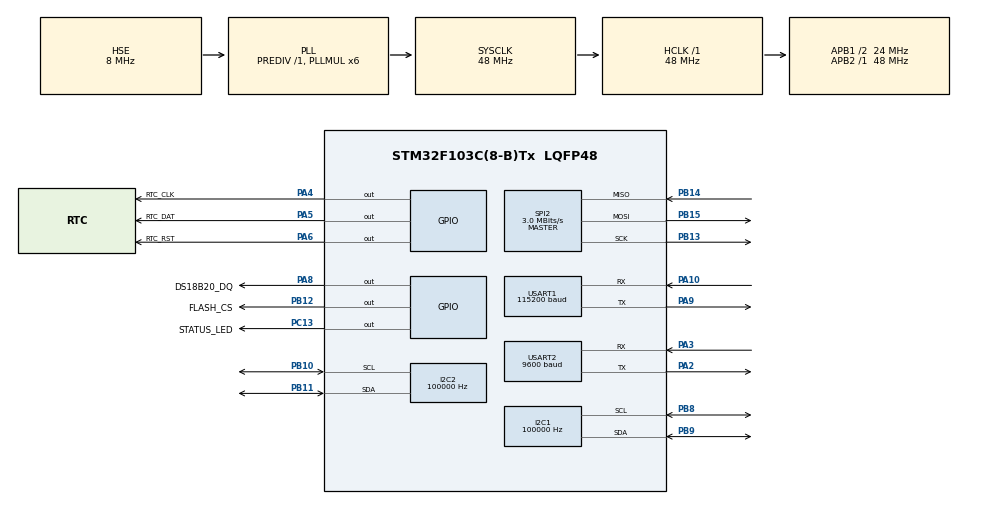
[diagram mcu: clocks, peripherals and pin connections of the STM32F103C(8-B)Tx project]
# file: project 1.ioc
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I2C1.ClockSpeed=100000
I2C2.ClockSpeed=100000
Mcu.Family=STM32F1
Mcu.Name=STM32F103C(8-B)Tx
Mcu.Package=LQFP48
NVIC.PriorityGroup=NVIC_PRIORITYGROUP_4
NVIC.USART1_IRQn=true\:0\:0\:false\:false\:true\:true\:true\:true
NVIC.USART2_IRQn=true\:1\:0\:false\:false\:true\:true\:true\:true
PA10.Mode=Asynchronous
PA10.Signal=USART1_RX
PA2.Mode=Asynchronous
PA2.Signal=USART2_TX
PA3.Mode=Asynchronous
PA3.Signal=USART2_RX
PA4.GPIO_Label=RTC_CLK
PA4.GPIO_Speed=GPIO_SPEED_FREQ_LOW
PA4.PinState=GPIO_PIN_RESET
PA4.Signal=GPIO_Output
PA5.GPIO_Label=RTC_DAT
PA5.GPIO_Speed=GPIO_SPEED_FREQ_LOW
PA5.PinState=GPIO_PIN_RESET
PA5.Signal=GPIO_Output
PA6.GPIO_Label=RTC_RST
PA6.GPIO_Speed=GPIO_SPEED_FREQ_LOW
PA6.PinState=GPIO_PIN_RESET
PA6.Signal=GPIO_Output
PA13.Mode=Serial_Wire
PA13.Signal=SYS_JTMS-SWDIO
PA14.Mode=Serial_Wire
PA14.Signal=SYS_JTCK-SWCLK
PA8.GPIO_Label=DS18B20_DQ
PA8.GPIO_ModeDefaultOutputPP=GPIO_MODE_OUTPUT_OD
PA8.GPIO_PuPd=GPIO_NOPULL
PA8.GPIO_Speed=GPIO_SPEED_FREQ_HIGH
PA8.PinState=GPIO_PIN_SET
PA8.Signal=GPIO_Output
PA9.Mode=Asynchronous
PA9.Signal=USART1_TX
PB13.Mode=Full_Duplex_Master
PB13.Signal=SPI2_SCK
PB14.Mode=Full_Duplex_Master
PB14.Signal=SPI2_MISO
PB15.Mode=Full_Duplex_Master
PB15.Signal=SPI2_MOSI
PB10.Mode=I2C
PB10.Signal=I2C2_SCL
PB11.Mode=I2C
PB11.Signal=I2C2_SDA
PB12.GPIO_Label=FLASH_CS
PB12.GPIO_Speed=GPIO_SPEED_FREQ_HIGH
PB12.PinState=GPIO_PIN_SET
PB12.Signal=GPIO_Output
PB8.Mode=I2C
PB8.Signal=I2C1_SCL
PB9.Mode=I2C
PB9.Signal=I2C1_SDA
PC13-TAMPER-RTC.GPIO_Label=STATUS_LED
PC13-TAMPER-RTC.PinState=GPIO_PIN_SET
PC13-TAMPER-RTC.Signal=GPIO_Output
PD0-OSC_IN.Mode=HSE-External-Oscillator
PD0-OSC_IN.Signal=RCC_OSC_IN
PD1-OSC_OUT.Mode=HSE-External-Oscillator
PD1-OSC_OUT.Signal=RCC_OSC_OUT
ProjectManager.HeapSize=0x200
ProjectManager.StackSize=0x400
ProjectManager.TargetToolchain=STM32CubeIDE
RCC.AHBFreq_Value=48000000
RCC.APB1CLKDivider=RCC_HCLK_DIV2
RCC.APB1Freq_Value=24000000
RCC.APB1TimFreq_Value=48000000
RCC.APB2Freq_Value=48000000
RCC.APB2TimFreq_Value=48000000
RCC.HCLKFreq_Value=48000000
RCC.PLLMUL=RCC_PLL_MUL6
RCC.PLLSourceVirtual=RCC_PLLSOURCE_HSE
RCC.SYSCLKFreq_VALUE=48000000
RCC.SYSCLKSource=RCC_SYSCLKSOURCE_PLLCLK
RCC.USBFreq_Value=48000000
SPI2.BaudRatePrescaler=SPI_BAUDRATEPRESCALER_8
SPI2.CalculateBaudRate=3.0 MBits/s
SPI2.Direction=SPI_DIRECTION_2LINES
SPI2.Mode=SPI_MODE_MASTER
SPI2.VirtualType=VM_MASTER
USART1.BaudRate=115200
USART1.VirtualMode=VM_ASYNC
USART2.BaudRate=9600
USART2.VirtualMode=VM_ASYNC
board=custom

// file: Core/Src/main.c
/* USER CODE BEGIN Header */
/**
  ******************************************************************************
  * @file           : main.c
  * @brief          : Main program body
  ******************************************************************************
  */
/* USER CODE END Header */
#include "main.h"

/* USER CODE BEGIN Includes */
#include "app.h"
/* USER CODE END Includes */

I2C_HandleTypeDef hi2c1;
I2C_HandleTypeDef hi2c2;

SPI_HandleTypeDef hspi2;

UART_HandleTypeDef huart1;
UART_HandleTypeDef huart2;

void SystemClock_Config(void);
static void MX_GPIO_Init(void);
static void MX_USART1_UART_Init(void);
static void MX_USART2_UART_Init(void);
static void MX_SPI2_Init(void);
static void MX_I2C1_Init(void);
static void MX_I2C2_Init(void);

int main(void)
{

  /* MCU Configuration--------------------------------------------------------*/

  /* Reset of all peripherals, Initializes the Flash interface and the Systick. */
  HAL_Init();

  /* Configure the system clock */
  SystemClock_Config();

  /* Initialize all configured peripherals */
  MX_GPIO_Init();
  MX_USART1_UART_Init();
  MX_USART2_UART_Init();
  MX_SPI2_Init();
  MX_I2C1_Init();
  MX_I2C2_Init();
  /* USER CODE BEGIN 2 */
  App_Init(&huart1, &huart2, &hi2c1, &hi2c2, &hspi2);
  /* USER CODE END 2 */

  /* Infinite loop */
  while (1)
  {

    /* USER CODE BEGIN 3 */
    App_Process();
    HAL_Delay(1U);
  }
  /* USER CODE END 3 */
}

void SystemClock_Config(void)
{
  RCC_OscInitTypeDef RCC_OscInitStruct = {0};
  RCC_ClkInitTypeDef RCC_ClkInitStruct = {0};

  /** Initializes the RCC Oscillators according to the specified parameters
  * in the RCC_OscInitTypeDef structure.
  */
  RCC_OscInitStruct.OscillatorType = RCC_OSCILLATORTYPE_HSE;
  RCC_OscInitStruct.HSEState = RCC_HSE_ON;
  RCC_OscInitStruct.HSEPredivValue = RCC_HSE_PREDIV_DIV1;
  RCC_OscInitStruct.HSIState = RCC_HSI_ON;
  RCC_OscInitStruct.PLL.PLLState = RCC_PLL_ON;
  RCC_OscInitStruct.PLL.PLLSource = RCC_PLLSOURCE_HSE;
  RCC_OscInitStruct.PLL.PLLMUL = RCC_PLL_MUL6;
  if (HAL_RCC_OscConfig(&RCC_OscInitStruct) != HAL_OK)
  {
    Error_Handler();
  }

  /** Initializes the CPU, AHB and APB buses clocks
  */
  RCC_ClkInitStruct.ClockType = RCC_CLOCKTYPE_HCLK|RCC_CLOCKTYPE_SYSCLK
                              |RCC_CLOCKTYPE_PCLK1|RCC_CLOCKTYPE_PCLK2;
  RCC_ClkInitStruct.SYSCLKSource = RCC_SYSCLKSOURCE_PLLCLK;
  RCC_ClkInitStruct.AHBCLKDivider = RCC_SYSCLK_DIV1;
  RCC_ClkInitStruct.APB1CLKDivider = RCC_HCLK_DIV2;
  RCC_ClkInitStruct.APB2CLKDivider = RCC_HCLK_DIV1;

  if (HAL_RCC_ClockConfig(&RCC_ClkInitStruct, FLASH_LATENCY_1) != HAL_OK)
  {
    Error_Handler();
  }
}

static void MX_I2C1_Init(void)
{

  hi2c1.Instance = I2C1;
  hi2c1.Init.ClockSpeed = 100000;
  hi2c1.Init.DutyCycle = I2C_DUTYCYCLE_2;
  hi2c1.Init.OwnAddress1 = 0;
  hi2c1.Init.AddressingMode = I2C_ADDRESSINGMODE_7BIT;
  hi2c1.Init.DualAddressMode = I2C_DUALADDRESS_DISABLE;
  hi2c1.Init.OwnAddress2 = 0;
  hi2c1.Init.GeneralCallMode = I2C_GENERALCALL_DISABLE;
  hi2c1.Init.NoStretchMode = I2C_NOSTRETCH_DISABLE;
  if (HAL_I2C_Init(&hi2c1) != HAL_OK)
  {
    Error_Handler();
  }

}

static void MX_I2C2_Init(void)
{

  hi2c2.Instance = I2C2;
  hi2c2.Init.ClockSpeed = 100000;
  hi2c2.Init.DutyCycle = I2C_DUTYCYCLE_2;
  hi2c2.Init.OwnAddress1 = 0;
  hi2c2.Init.AddressingMode = I2C_ADDRESSINGMODE_7BIT;
  hi2c2.Init.DualAddressMode = I2C_DUALADDRESS_DISABLE;
  hi2c2.Init.OwnAddress2 = 0;
  hi2c2.Init.GeneralCallMode = I2C_GENERALCALL_DISABLE;
  hi2c2.Init.NoStretchMode = I2C_NOSTRETCH_DISABLE;
  if (HAL_I2C_Init(&hi2c2) != HAL_OK)
  {
    Error_Handler();
  }

}

static void MX_SPI2_Init(void)
{

  /* SPI2 parameter configuration*/
  hspi2.Instance = SPI2;
  hspi2.Init.Mode = SPI_MODE_MASTER;
  hspi2.Init.Direction = SPI_DIRECTION_2LINES;
  hspi2.Init.DataSize = SPI_DATASIZE_8BIT;
  hspi2.Init.CLKPolarity = SPI_POLARITY_LOW;
  hspi2.Init.CLKPhase = SPI_PHASE_1EDGE;
  hspi2.Init.NSS = SPI_NSS_SOFT;
  hspi2.Init.BaudRatePrescaler = SPI_BAUDRATEPRESCALER_8;
  hspi2.Init.FirstBit = SPI_FIRSTBIT_MSB;
  hspi2.Init.TIMode = SPI_TIMODE_DISABLE;
  hspi2.Init.CRCCalculation = SPI_CRCCALCULATION_DISABLE;
  hspi2.Init.CRCPolynomial = 10;
  if (HAL_SPI_Init(&hspi2) != HAL_OK)
  {
    Error_Handler();
  }

}

static void MX_USART1_UART_Init(void)
{

  huart1.Instance = USART1;
  huart1.Init.BaudRate = 115200;
  huart1.Init.WordLength = UART_WORDLENGTH_8B;
  huart1.Init.StopBits = UART_STOPBITS_1;
  huart1.Init.Parity = UART_PARITY_NONE;
  huart1.Init.Mode = UART_MODE_TX_RX;
  huart1.Init.HwFlowCtl = UART_HWCONTROL_NONE;
  huart1.Init.OverSampling = UART_OVERSAMPLING_16;
  if (HAL_UART_Init(&huart1) != HAL_OK)
  {
    Error_Handler();
  }

}

static void MX_USART2_UART_Init(void)
{

  huart2.Instance = USART2;
  huart2.Init.BaudRate = 9600;
  huart2.Init.WordLength = UART_WORDLENGTH_8B;
  huart2.Init.StopBits = UART_STOPBITS_1;
  huart2.Init.Parity = UART_PARITY_NONE;
  huart2.Init.Mode = UART_MODE_TX_RX;
  huart2.Init.HwFlowCtl = UART_HWCONTROL_NONE;
  huart2.Init.OverSampling = UART_OVERSAMPLING_16;
  if (HAL_UART_Init(&huart2) != HAL_OK)
  {
    Error_Handler();
  }

}

static void MX_GPIO_Init(void)
{
  GPIO_InitTypeDef GPIO_InitStruct = {0};

  /* GPIO Ports Clock Enable */
  __HAL_RCC_GPIOC_CLK_ENABLE();
  __HAL_RCC_GPIOD_CLK_ENABLE();
  __HAL_RCC_GPIOB_CLK_ENABLE();
  __HAL_RCC_GPIOA_CLK_ENABLE();

  /*Configure GPIO pin Output Level */
  HAL_GPIO_WritePin(STATUS_LED_GPIO_Port, STATUS_LED_Pin, GPIO_PIN_SET);

  /*Configure GPIO pin Output Level */
  HAL_GPIO_WritePin(DS18B20_DQ_GPIO_Port, DS18B20_DQ_Pin, GPIO_PIN_SET);

  /*Configure GPIO pin Output Level */
  HAL_GPIO_WritePin(GPIOA, RTC_CLK_Pin|RTC_DAT_Pin|RTC_RST_Pin, GPIO_PIN_RESET);

  /*Configure GPIO pin Output Level */
  HAL_GPIO_WritePin(FLASH_CS_GPIO_Port, FLASH_CS_Pin, GPIO_PIN_SET);

  /*Configure GPIO pin : STATUS_LED_Pin */
  GPIO_InitStruct.Pin = STATUS_LED_Pin;
  GPIO_InitStruct.Mode = GPIO_MODE_OUTPUT_PP;
  GPIO_InitStruct.Pull = GPIO_NOPULL;
  GPIO_InitStruct.Speed = GPIO_SPEED_FREQ_LOW;
  HAL_GPIO_Init(STATUS_LED_GPIO_Port, &GPIO_InitStruct);

  /*Configure GPIO pin : DS18B20_DQ_Pin */
  GPIO_InitStruct.Pin = DS18B20_DQ_Pin;
  GPIO_InitStruct.Mode = GPIO_MODE_OUTPUT_OD;
  GPIO_InitStruct.Pull = GPIO_NOPULL;
  GPIO_InitStruct.Speed = GPIO_SPEED_FREQ_HIGH;
  HAL_GPIO_Init(DS18B20_DQ_GPIO_Port, &GPIO_InitStruct);

  /*Configure GPIO pins : RTC_CLK_Pin RTC_DAT_Pin RTC_RST_Pin */
  GPIO_InitStruct.Pin = RTC_CLK_Pin|RTC_DAT_Pin|RTC_RST_Pin;
  GPIO_InitStruct.Mode = GPIO_MODE_OUTPUT_PP;
  GPIO_InitStruct.Pull = GPIO_NOPULL;
  GPIO_InitStruct.Speed = GPIO_SPEED_FREQ_LOW;
  HAL_GPIO_Init(GPIOA, &GPIO_InitStruct);

  /*Configure GPIO pin : FLASH_CS_Pin */
  GPIO_InitStruct.Pin = FLASH_CS_Pin;
  GPIO_InitStruct.Mode = GPIO_MODE_OUTPUT_PP;
  GPIO_InitStruct.Pull = GPIO_NOPULL;
  GPIO_InitStruct.Speed = GPIO_SPEED_FREQ_HIGH;
  HAL_GPIO_Init(FLASH_CS_GPIO_Port, &GPIO_InitStruct);

}

void Error_Handler(void)
{
  __disable_irq();
  while (1)
  {
  }
}
